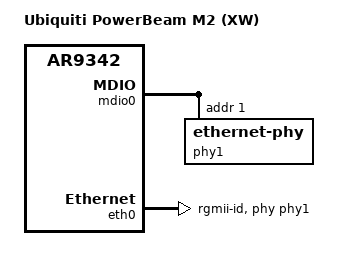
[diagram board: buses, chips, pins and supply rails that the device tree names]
// SPDX-License-Identifier: GPL-2.0-or-later OR MIT

#include "ar9342_ubnt_xw.dtsi"

/ {
	compatible = "ubnt,powerbeam-m2-xw", "ubnt,xw", "qca,ar9342";
	model = "Ubiquiti PowerBeam M2 (XW)";
};

&mdio0 {
	status = "okay";

	phy-mask = <4>;

	phy1: ethernet-phy@1 {
		reg = <1>;
	};
};

&eth0 {
	status = "okay";

	/* default for ar934x, except for 1000M and 10M */
	pll-data = <0x02000000 0x00000101 0x00001313>;

	phy-mode = "rgmii-id";
	phy-handle = <&phy1>;

	gmac-config {
		device = <&gmac>;
		rxd-delay = <3>;
		rxdv-delay = <3>;
	};
};
